# m52363b register map
Vendor: Elmos Semiconductor SE; Series: Integrated Driver; File version: 1.0
CPU: CM23 r1p0, little endian, MPU, no FPU, VTOR, 2 interrupt priority bits, 13 interrupts
Registers are 16-bit, read-write, reset 0x0 unless marked. A register's access mark holds for its fields unless they carry their own. Offsets are from the block's base; [hi:lo] are bit positions.

## LINSCI — LINSCI module
Base 0x51000000
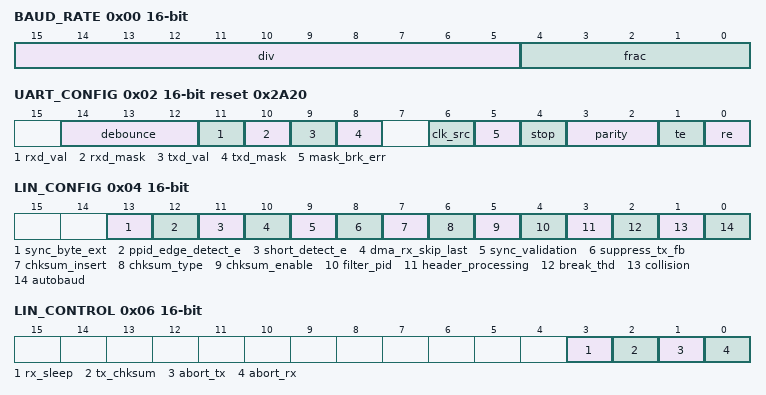
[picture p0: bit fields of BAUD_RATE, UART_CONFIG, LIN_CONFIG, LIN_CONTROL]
0x00 BAUD_RATE
  [15:5] div — div bitfield
  [4:0] frac — frac bitfield
0x02 UART_CONFIG reset 0x2A20
  [14:12] debounce — debounce bitfield
  [11] rxd_val ro — rxd_val bitfield
  [10] rxd_mask — rxd_mask bitfield
  [9] txd_val — txd_val bitfield
  [8] txd_mask — txd_mask bitfield
  [6] clk_src — clk_src bitfield
  [5] mask_brk_err — mask_brk_err bitfield
  [4] stop — stop bitfield
  [3:2] parity — parity bitfield
  [1] te — te bitfield
  [0] re — re bitfield
0x04 LIN_CONFIG
  [13] sync_byte_ext — sync_byte_ext bitfield
  [12] ppid_edge_detect_e — ppid_edge_detect_e bitfield
  [11] short_detect_e — short_detect_e bitfield
  [10] dma_rx_skip_last — dma_rx_skip_last bitfield
  [9] sync_validation — sync_validation bitfield
  [8] suppress_tx_fb — suppress_tx_fb bitfield
  [7] chksum_insert — chksum_insert bitfield
  [6] chksum_type — chksum_type bitfield
  [5] chksum_enable — chksum_enable bitfield
  [4] filter_pid — filter_pid bitfield
  [3] header_processing — header_processing bitfield
  [2] break_thd — break_thd bitfield
  [1] collision — collision bitfield
  [0] autobaud — autobaud bitfield
0x06 LIN_CONTROL (reset mask 0xC)
  [3] rx_sleep — rx_sleep bitfield
  [2] tx_chksum — tx_chksum bitfield
  [1] abort_tx wo — abort_tx bitfield
  [0] abort_rx wo — abort_rx bitfield
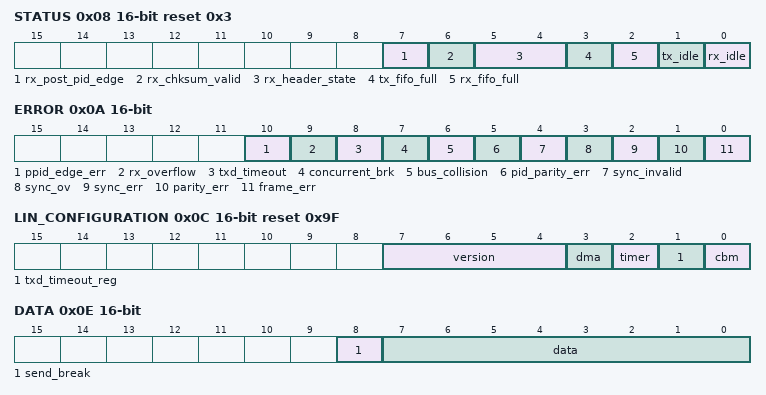
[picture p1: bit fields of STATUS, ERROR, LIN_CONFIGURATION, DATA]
0x08 STATUS ro reset 0x3
  [7] rx_post_pid_edge — rx_post_pid_edge bitfield
  [6] rx_chksum_valid — rx_chksum_valid bitfield
  [5:4] rx_header_state — rx_header_state bitfield
  [3] tx_fifo_full — tx_fifo_full bitfield
  [2] rx_fifo_full — rx_fifo_full bitfield
  [1] tx_idle — tx_idle bitfield
  [0] rx_idle — rx_idle bitfield
0x0A ERROR
  [10] ppid_edge_err — ppid_edge_err bitfield
  [9] rx_overflow — rx_overflow bitfield
  [8] txd_timeout — txd_timeout bitfield
  [7] concurrent_brk — concurrent_brk bitfield
  [6] bus_collision — bus_collision bitfield
  [5] pid_parity_err — pid_parity_err bitfield
  [4] sync_invalid — sync_invalid bitfield
  [3] sync_ov — sync_ov bitfield
  [2] sync_err — sync_err bitfield
  [1] parity_err — parity_err bitfield
  [0] frame_err — frame_err bitfield
0x0C LIN_CONFIGURATION ro reset 0x9F
  [7:4] version — version bitfield
  [3] dma — dma bitfield
  [2] timer — timer bitfield
  [1] txd_timeout_reg — txd_timeout_reg bitfield
  [0] cbm — cbm bitfield
0x0E DATA (reset mask 0xFF)
  [8] send_break wo — send_break bitfield
  [7:0] data — data bitfield
0x10 TBIT2_LENGTH ro
  [15:0] data — data bitfield
0x12 LIN_PID ro
  [7:0] data — data bitfield
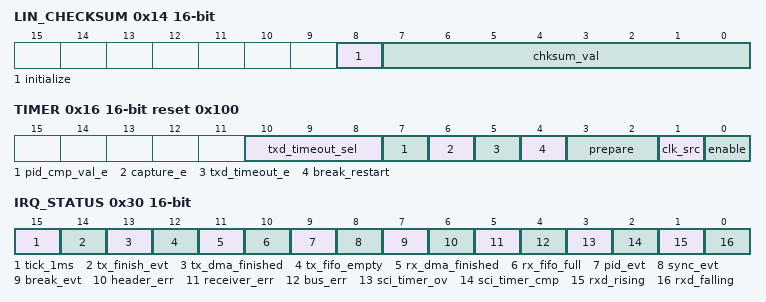
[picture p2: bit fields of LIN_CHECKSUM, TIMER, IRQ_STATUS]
0x14 LIN_CHECKSUM (reset mask 0xFF)
  [8] initialize wo — initialize bitfield
  [7:0] chksum_val — chksum_val bitfield
0x16 TIMER reset 0x100
  [10:8] txd_timeout_sel — txd_timeout_sel bitfield
  [7] pid_cmp_val_e — pid_cmp_val_e bitfield
  [6] capture_e — capture_e bitfield
  [5] txd_timeout_e — txd_timeout_e bitfield
  [4] break_restart — break_restart bitfield
  [3:2] prepare — prepare bitfield
  [1] clk_src — clk_src bitfield
  [0] enable — enable bitfield
0x18 TIMER_COUNTER ro
  [15:0] timer_counter — timer_counter bitfield
0x1A TIMER_COMPARE
  [15:0] timer_compare — timer_compare bitfield
0x1C TIMER_CAPTURE ro
  [15:0] timer_capture — timer_capture bitfield
0x20 DMA_TX_ADDRESS
  [15:0] dma_tx_addr — dma_tx_addr bitfield
0x22 DMA_TX_ADDRESS_HIGH
  [15:0] dma_tx_addr — dma_tx_addr bitfield
0x24 DMA_TX_LENGTH
  [7:0] dma_tx_length — dma_tx_length bitfield
0x28 DMA_RX_ADDRESS
  [15:0] dma_rx_addr — dma_rx_addr bitfield
0x2A DMA_RX_ADDRESS_HIGH
  [15:0] dma_rx_addr — dma_rx_addr bitfield
0x2C DMA_RX_LENGTH
  [7:0] dma_rx_length — dma_rx_length bitfield
0x30 IRQ_STATUS
  [15] tick_1ms — tick_1ms bitfield
  [14] tx_finish_evt — tx_finish_evt bitfield
  [13] tx_dma_finished — tx_dma_finished bitfield
  [12] tx_fifo_empty ro — tx_fifo_empty bitfield
  [11] rx_dma_finished — rx_dma_finished bitfield
  [10] rx_fifo_full ro — rx_fifo_full bitfield
  [9] pid_evt — pid_evt bitfield
  [8] sync_evt — sync_evt bitfield
  [7] break_evt — break_evt bitfield
  [6] header_err ro — header_err bitfield
  [5] receiver_err ro — receiver_err bitfield
  [4] bus_err ro — bus_err bitfield
  [3] sci_timer_ov — sci_timer_ov bitfield
  [2] sci_timer_cmp — sci_timer_cmp bitfield
  [1] rxd_rising — rxd_rising bitfield
  [0] rxd_falling — rxd_falling bitfield
0x34 IRQ_MASK
  [15:0] mask — mask bitfield
0x38 IRQ_VENABLE wo reset not defined
  [3:0] vno — vno bitfield
0x3A IRQ_VDISABLE wo reset not defined
  [3:0] vno — vno bitfield
0x3C IRQ_VMAX reset 0x10
  [4:0] vmax — vmax bitfield
0x3E IRQ_VNO reset 0x10
  [4:0] vno — vno bitfield
